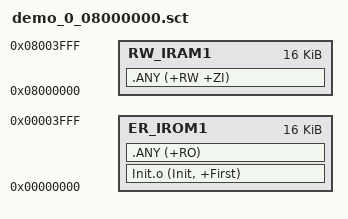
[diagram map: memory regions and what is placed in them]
; *************************************************************
; *** Scatter-Loading Description File generated by uVision ***
; *************************************************************

LR_IROM1 0x00000000 0x00004000  {    ; load region size_region
  ER_IROM1 0x00000000 0x00004000  {  ; load address = execution address
   Init.o (Init, +First)
   .ANY (+RO)
  }
  RW_IRAM1 0x08000000 0x00004000  {  ; RW data
   .ANY (+RW +ZI)
  }
}

